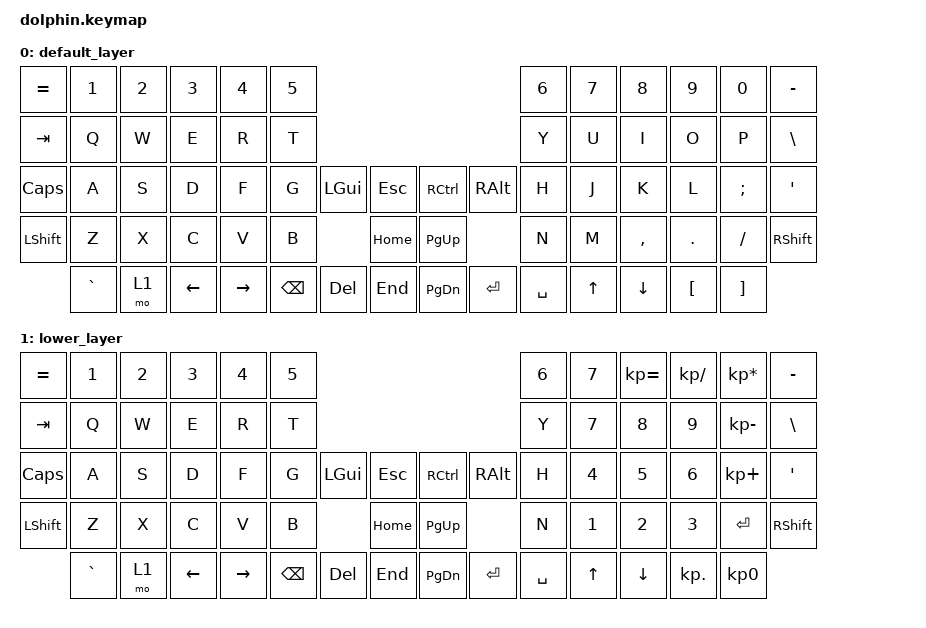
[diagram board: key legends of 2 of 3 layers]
/*
 * Copyright (c) 2020 The ZMK Contributors
 *
 * SPDX-License-Identifier: MIT
 */

#include <behaviors.dtsi>
#include <dt-bindings/zmk/keys.h>
#include <dt-bindings/zmk/bt.h>

/ {
        keymap {
                compatible = "zmk,keymap";

                default_layer {
// ------------------------------------------------------------------------------------------------------------------------------------------------
// | EQUAL|  N1  |  N2  |  N3  |  N4   |  N5   |       |       |     |       |       |   N6  |   N7   |   N8    |   N9   |   N0   |  MINUS |
// | TAB  |  Q   |  W   |  E   |  R    |  T    |       |       |     |       |       |   Y   |   U    |   I     |   O    |   P    |  BSLH  |
// | CAPS |  A   |  S   |  D   |  F    |  G    | LGUI  | ESC   |     | RCTRL | RALT  |   H   |   J    |   K     |   L    |  SEMI  |  SQT   |
// | LSHFT|  Z   |  X   |  C   |  V    |  B    |       | HOME  |     | PG_UP |       |   N   |   M    |  COMMA  |  DOT   |  FSLH  | RSHFT  |
//        | GRAVE| mo1  | LEFT | RIGHT | BSPC  | DEL   | END   |     | PG_DN | ENTER | SPACE |   UP   |  DOWN   |  LBKT  |  RBKT  |
                  bindings = <
                    &kp EQUAL &kp N1    &kp N2   &kp N3   &kp N4    &kp N5                                           &kp N6    &kp N7 &kp N8    &kp N9   &kp N0    &kp MINUS 
                    &kp TAB   &kp Q     &kp W    &kp E    &kp R     &kp T                                            &kp Y     &kp U  &kp I     &kp O    &kp P     &kp BSLH 
                    &kp CAPS  &kp A     &kp S    &kp D    &kp F     &kp G    &kp LGUI &kp ESC    &kp RCTRL &kp RALT  &kp H     &kp J  &kp K     &kp L    &kp SEMI  &kp SQT
                    &kp LSHFT &kp Z     &kp X    &kp C    &kp V     &kp B             &kp HOME   &kp PG_UP           &kp N     &kp M  &kp COMMA &kp DOT  &kp FSLH  &kp RSHFT
                              &kp GRAVE &mo 1    &kp LEFT &kp RIGHT &kp BSPC &kp DEL  &kp END    &kp PG_DN &kp ENTER &kp SPACE &kp UP &kp DOWN  &kp LBKT &kp RBKT
                  >;
                };
                lower_layer {
// ------------------------------------------------------------------------------------------------------------------------------------------------
// | EQUAL|  N1  |  N2  |  N3  |  N4   |  N5   |       |       |     |       |       |   N6  |   N7   | KP_EQUAL | KP_DIVIDE |  KP_MULTIPLY  |  MINUS |
// | BTCLR|  BT1 |  BT2 |  BT3 |  BT4  |  BT5  |       |       |     |       |       |   Y   |   7    |   8      |   9       |  KP_MINUS     |  BSLH  |
// | CAPS |  A   |  S   |  D   |  F    |  G    | LGUI  | ESC   |     | RCTRL | RALT  |   H   |   4    |   5      |   6       |  KP_PLUS      |  SQT   |
// | LSHFT|  Z   |  X   |  C   |  V    |  B    |       | HOME  |     | PG_UP |       |   N   |   1    |   2      |   3       |  ENTER        | RSHFT  |
//        | GRAVE| mo1  | LEFT | RIGHT | BSPC  | DEL   | END   |     | PG_DN | ENTER | SPACE |  UP    |  DOWN    |  KP_DOT   |  KP_N0        |
                        bindings = <
                    &kp EQUAL &kp N1    &kp N2   &kp N3   &kp N4    &kp N5                                           &kp N6    &kp N7 &kp KP_EQUAL &kp KP_DIVIDE &kp KP_MULTIPLY &kp MINUS 
                    &kp TAB   &kp Q     &kp W    &kp E    &kp R     &kp T                                            &kp Y     &kp 7  &kp 8        &kp 9         &kp KP_MINUS    &kp BSLH 
                    &kp CAPS  &kp A     &kp S    &kp D    &kp F     &kp G    &kp LGUI &kp ESC    &kp RCTRL &kp RALT  &kp H     &kp 4  &kp 5        &kp 6         &kp KP_PLUS     &kp SQT
                    &kp LSHFT &kp Z     &kp X    &kp C    &kp V     &kp B             &kp HOME   &kp PG_UP           &kp N     &kp 1  &kp 2        &kp 3         &kp ENTER       &kp RSHFT
                              &kp GRAVE &mo 1    &kp LEFT &kp RIGHT &kp BSPC &kp DEL  &kp END    &kp PG_DN &kp ENTER &kp SPACE &kp UP &kp DOWN     &kp KP_DOT    &kp KP_N0
                        >;
                };

                raise_layer {
// -----------------------------------------------------------------------------------------
// |  TAB |  !  |  @  |  #  |  $  |  %  |   |  ^  |  &  |  *  |  (  |  )  | BSPC |
// | CTRL |     |     |     |     |     |   |  -  |  =  |  [  |  ]  |  \  |  `   |
// | SHFT |     |     |     |     |     |   |  _  |  +  |  {  |  }  | "|" |  ~   |
//                    | GUI |     | SPC |   | ENT |     | ALT |
                        bindings = <
   &kp  TAB  &kp EXCL &kp AT &kp HASH &kp DLLR &kp PRCNT   &kp CARET &kp AMPS  &kp ASTRK &kp LPAR &kp RPAR &kp BSPC
   &kp LCTRL &trans   &trans &trans   &trans   &trans      &kp MINUS &kp EQUAL &kp LBKT  &kp RBKT &kp BSLH &kp GRAVE
   &kp LSHFT &trans   &trans &trans   &trans   &trans      &kp UNDER &kp PLUS  &kp LBRC  &kp RBRC &kp PIPE &kp TILDE
                             &kp LGUI &trans   &kp SPACE   &kp RET   &trans    &kp RALT
                        >;
                };
        };
};
